# vpac_targetdb register map
Vendor: Texas Instruments
Registers are 32-bit, read-write, no defined reset value unless marked. A register's access mark holds for its fields unless they carry their own. Offsets are as the file gives them; [hi:lo] are bit positions; {n}, {i} and the like mark numbered series; 'fields as' and 'values as' point back to an identical list.

## VPAC (part 6 of 8) — Vision Pre-Processing Accelerator (VPAC)
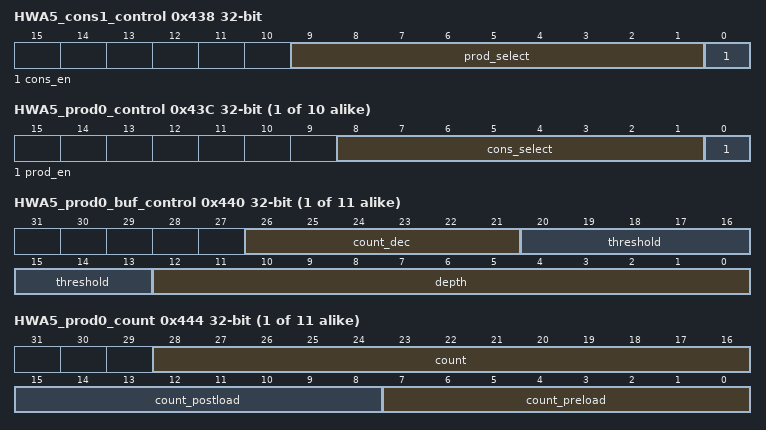
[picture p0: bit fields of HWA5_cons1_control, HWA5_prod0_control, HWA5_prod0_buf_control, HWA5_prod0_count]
0x438 HWA5_cons1_control — Controlling consumer socket 1 for HWA5
  [9:1] prod_select — producer select for HWA5 cons socket 1
  [0] cons_en — '1' -> Consumer socket 1 enable , '0' Disable
{0x43C+0x14*i} HWA5_prod{i}_control (i=0..9) — Controlling producer socket{i} for HWA5
  [8:1] cons_select — consumer select for HWA5 prod socket {i}. Used in decrementing count of producer buffer
  [0] prod_en — '1' -> Producer socket 0 enable , '0' Disable
{0x440+0x14*i} HWA5_prod{i}_buf_control (i=0..10) — Controlling producer socket{i} buffer for HWA5
  [26:21] count_dec — Count decrement value for prod count
  [20:13] threshold — Count threshold to generate pend for consumer
  [12:0] depth — Maximum number of producer buffer count
{0x444+0x14*i} HWA5_prod{i}_count access per field (i=0..10) — Defining count values for pre/post load for generating pend by HWA5 prod{i}
  [28:16] count ro — current count value
  [15:8] count_postload rw — count postload after producer max thread count reached
  [7:0] count_preload rw — count preload after scheduler start/init
{0x2D4+4i} GLBCE_WDR_GAMMA_LUT_{i} access per field (i=100..256) — Frontend WDR LUT
  [15:0] VAL rw — LUT Value
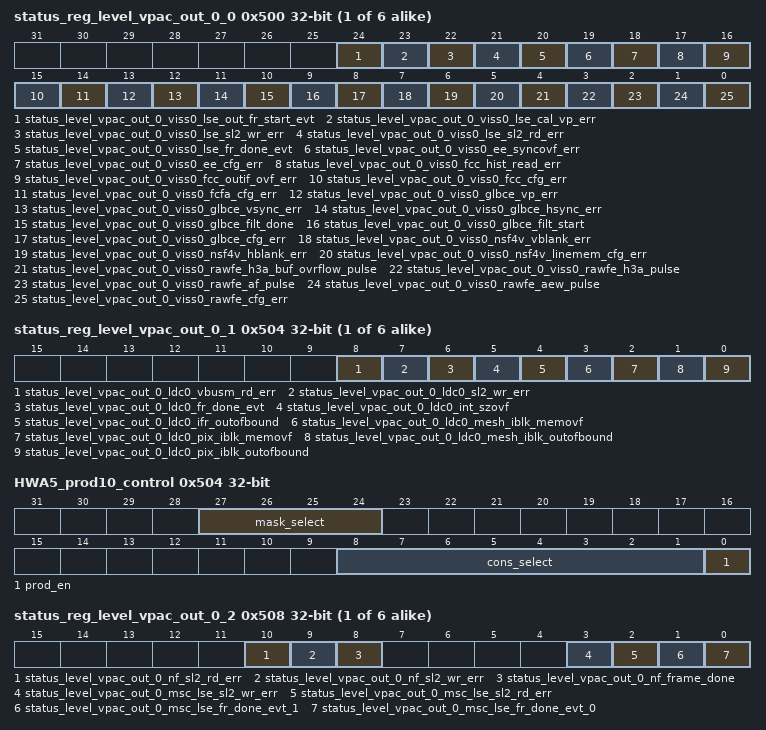
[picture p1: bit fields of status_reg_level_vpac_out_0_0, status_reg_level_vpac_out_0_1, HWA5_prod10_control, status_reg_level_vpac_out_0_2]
{0x500+0x20*i} status_reg_level_vpac_out_{i}_0 (i=0..5) — Status Register {8i}
  [24] status_level_vpac_out_{i}_viss0_lse_out_fr_start_evt — Status ,write 1 to set, for level_vpac_out_{i}_en_viss0_lse_out_fr_start_evt
  [23] status_level_vpac_out_{i}_viss0_lse_cal_vp_err — Status ,write 1 to set, for level_vpac_out_{i}_en_viss0_lse_cal_vp_err
  [22] status_level_vpac_out_{i}_viss0_lse_sl2_wr_err — Status ,write 1 to set, for level_vpac_out_{i}_en_viss0_lse_sl2_wr_err
  [21] status_level_vpac_out_{i}_viss0_lse_sl2_rd_err — Status ,write 1 to set, for level_vpac_out_{i}_en_viss0_lse_sl2_rd_err
  [20] status_level_vpac_out_{i}_viss0_lse_fr_done_evt — Status ,write 1 to set, for level_vpac_out_{i}_en_viss0_lse_fr_done_evt
  [19] status_level_vpac_out_{i}_viss0_ee_syncovf_err — Status ,write 1 to set, for level_vpac_out_{i}_en_viss0_ee_syncovf_err
  [18] status_level_vpac_out_{i}_viss0_ee_cfg_err — Status ,write 1 to set, for level_vpac_out_{i}_en_viss0_ee_cfg_err
  [17] status_level_vpac_out_{i}_viss0_fcc_hist_read_err — Status ,write 1 to set, for level_vpac_out_{i}_en_viss0_fcc_hist_read_err
  [16] status_level_vpac_out_{i}_viss0_fcc_outif_ovf_err — Status ,write 1 to set, for level_vpac_out_{i}_en_viss0_fcc_outif_ovf_err
  [15] status_level_vpac_out_{i}_viss0_fcc_cfg_err — Status ,write 1 to set, for level_vpac_out_{i}_en_viss0_fcc_cfg_err
  [14] status_level_vpac_out_{i}_viss0_fcfa_cfg_err — Status ,write 1 to set, for level_vpac_out_{i}_en_viss0_fcfa_cfg_err
  [13] status_level_vpac_out_{i}_viss0_glbce_vp_err — Status ,write 1 to set, for level_vpac_out_{i}_en_viss0_glbce_vp_err
  [12] status_level_vpac_out_{i}_viss0_glbce_vsync_err — Status ,write 1 to set, for level_vpac_out_{i}_en_viss0_glbce_vsync_err
  [11] status_level_vpac_out_{i}_viss0_glbce_hsync_err — Status ,write 1 to set, for level_vpac_out_{i}_en_viss0_glbce_hsync_err
  [10] status_level_vpac_out_{i}_viss0_glbce_filt_done — Status ,write 1 to set, for level_vpac_out_{i}_en_viss0_glbce_filt_done
  [9] status_level_vpac_out_{i}_viss0_glbce_filt_start — Status ,write 1 to set, for level_vpac_out_{i}_en_viss0_glbce_filt_start
  [8] status_level_vpac_out_{i}_viss0_glbce_cfg_err — Status ,write 1 to set, for level_vpac_out_{i}_en_viss0_glbce_cfg_err
  [7] status_level_vpac_out_{i}_viss0_nsf4v_vblank_err — Status ,write 1 to set, for level_vpac_out_{i}_en_viss0_nsf4v_vblank_err
  [6] status_level_vpac_out_{i}_viss0_nsf4v_hblank_err — Status ,write 1 to set, for level_vpac_out_{i}_en_viss0_nsf4v_hblank_err
  [5] status_level_vpac_out_{i}_viss0_nsf4v_linemem_cfg_err — Status ,write 1 to set, for level_vpac_out_{i}_en_viss0_nsf4v_linemem_cfg_err
  [4] status_level_vpac_out_{i}_viss0_rawfe_h3a_buf_ovrflow_pulse — Status ,write 1 to set, for level_vpac_out_{i}_en_viss0_rawfe_h3a_buf_ovrflow_pulse
  [3] status_level_vpac_out_{i}_viss0_rawfe_h3a_pulse — Status ,write 1 to set, for level_vpac_out_{i}_en_viss0_rawfe_h3a_pulse
  [2] status_level_vpac_out_{i}_viss0_rawfe_af_pulse — Status ,write 1 to set, for level_vpac_out_{i}_en_viss0_rawfe_af_pulse
  [1] status_level_vpac_out_{i}_viss0_rawfe_aew_pulse — Status ,write 1 to set, for level_vpac_out_{i}_en_viss0_rawfe_aew_pulse
  [0] status_level_vpac_out_{i}_viss0_rawfe_cfg_err — Status ,write 1 to set, for level_vpac_out_{i}_en_viss0_rawfe_cfg_err
{0x504+0x20*i} status_reg_level_vpac_out_{i}_1 (i=0..5) — Status Register {8i+1}
  [8] status_level_vpac_out_{i}_ldc0_vbusm_rd_err — Status ,write 1 to set, for level_vpac_out_{i}_en_ldc0_vbusm_rd_err
  [7] status_level_vpac_out_{i}_ldc0_sl2_wr_err — Status ,write 1 to set, for level_vpac_out_{i}_en_ldc0_sl2_wr_err
  [6] status_level_vpac_out_{i}_ldc0_fr_done_evt — Status ,write 1 to set, for level_vpac_out_{i}_en_ldc0_fr_done_evt
  [5] status_level_vpac_out_{i}_ldc0_int_szovf — Status ,write 1 to set, for level_vpac_out_{i}_en_ldc0_int_szovf
  [4] status_level_vpac_out_{i}_ldc0_ifr_outofbound — Status ,write 1 to set, for level_vpac_out_{i}_en_ldc0_ifr_outofbound
  [3] status_level_vpac_out_{i}_ldc0_mesh_iblk_memovf — Status ,write 1 to set, for level_vpac_out_{i}_en_ldc0_mesh_iblk_memovf
  [2] status_level_vpac_out_{i}_ldc0_pix_iblk_memovf — Status ,write 1 to set, for level_vpac_out_{i}_en_ldc0_pix_iblk_memovf
  [1] status_level_vpac_out_{i}_ldc0_mesh_iblk_outofbound — Status ,write 1 to set, for level_vpac_out_{i}_en_ldc0_mesh_iblk_outofbound
  [0] status_level_vpac_out_{i}_ldc0_pix_iblk_outofbound — Status ,write 1 to set, for level_vpac_out_{i}_en_ldc0_pix_iblk_outofbound
0x504 HWA5_prod10_control — Controlling producer socket10 for HWA5
  [27:24] mask_select — define which tdone_mask apply to prod socket 10. tdone_mask[mask_select] applies to prod_socket10
  [8:1] cons_select — consumer select for HWA5 prod socket 10. Used in decrementing count of producer buffer
  [0] prod_en — '1' -> Producer socket 0 enable , '0' Disable
{0x508+0x20*i} status_reg_level_vpac_out_{i}_2 (i=0..5) — Status Register {8i+2}
  [10] status_level_vpac_out_{i}_nf_sl2_rd_err — Status ,write 1 to set, for level_vpac_out_{i}_en_nf_sl2_rd_err
  [9] status_level_vpac_out_{i}_nf_sl2_wr_err — Status ,write 1 to set, for level_vpac_out_{i}_en_nf_sl2_wr_err
  [8] status_level_vpac_out_{i}_nf_frame_done — Status ,write 1 to set, for level_vpac_out_{i}_en_nf_frame_done
  [3] status_level_vpac_out_{i}_msc_lse_sl2_wr_err — Status ,write 1 to set, for level_vpac_out_{i}_en_msc_lse_sl2_wr_err
  [2] status_level_vpac_out_{i}_msc_lse_sl2_rd_err — Status ,write 1 to set, for level_vpac_out_{i}_en_msc_lse_sl2_rd_err
  [1] status_level_vpac_out_{i}_msc_lse_fr_done_evt_1 — Status ,write 1 to set, for level_vpac_out_{i}_en_msc_lse_fr_done_evt_1
  [0] status_level_vpac_out_{i}_msc_lse_fr_done_evt_0 — Status ,write 1 to set, for level_vpac_out_{i}_en_msc_lse_fr_done_evt_0
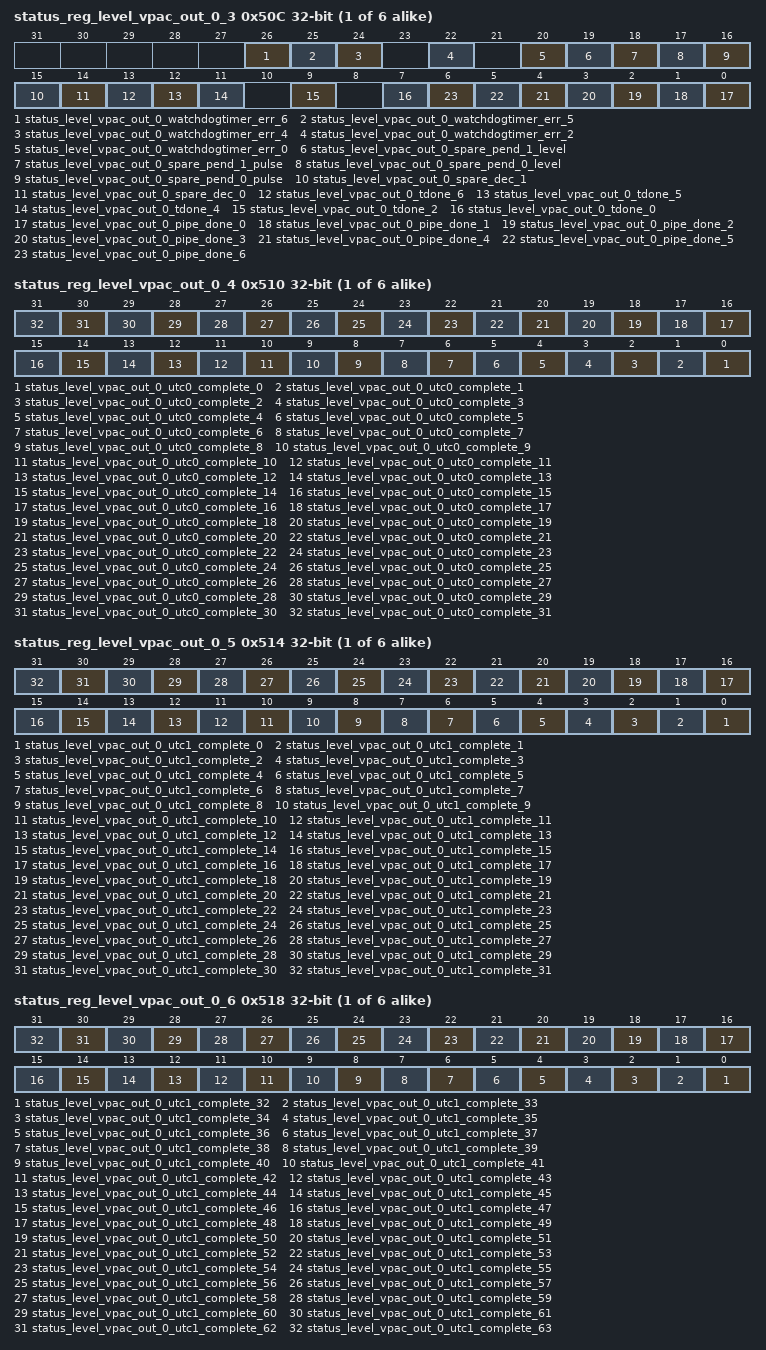
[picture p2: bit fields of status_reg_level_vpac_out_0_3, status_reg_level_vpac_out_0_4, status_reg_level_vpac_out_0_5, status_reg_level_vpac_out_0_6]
{0x50C+0x20*i} status_reg_level_vpac_out_{i}_3 access per field (i=0..5) — Status Register {8i+3}
  [26] status_level_vpac_out_{i}_watchdogtimer_err_6 rw — Status ,write 1 to set, for level_vpac_out_{i}_en_watchdogtimer_err_6
  [25] status_level_vpac_out_{i}_watchdogtimer_err_5 rw — Status ,write 1 to set, for level_vpac_out_{i}_en_watchdogtimer_err_5
  [24] status_level_vpac_out_{i}_watchdogtimer_err_4 rw — Status ,write 1 to set, for level_vpac_out_{i}_en_watchdogtimer_err_4
  [22] status_level_vpac_out_{i}_watchdogtimer_err_2 rw — Status ,write 1 to set, for level_vpac_out_{i}_en_watchdogtimer_err_2
  [20] status_level_vpac_out_{i}_watchdogtimer_err_0 rw — Status ,write 1 to set, for level_vpac_out_{i}_en_watchdogtimer_err_0
  [19] status_level_vpac_out_{i}_spare_pend_1_level ro — Status for level_vpac_out_{i}_en_spare_pend_1_level
  [18] status_level_vpac_out_{i}_spare_pend_1_pulse ro — Status for level_vpac_out_{i}_en_spare_pend_1_pulse
  [17] status_level_vpac_out_{i}_spare_pend_0_level ro — Status for level_vpac_out_{i}_en_spare_pend_0_level
  [16] status_level_vpac_out_{i}_spare_pend_0_pulse ro — Status for level_vpac_out_{i}_en_spare_pend_0_pulse
  [15] status_level_vpac_out_{i}_spare_dec_1 rw — Status ,write 1 to set, for level_vpac_out_{i}_en_spare_dec_1
  [14] status_level_vpac_out_{i}_spare_dec_0 rw — Status ,write 1 to set, for level_vpac_out_{i}_en_spare_dec_0
  [13] status_level_vpac_out_{i}_tdone_6 rw — Status ,write 1 to set, for level_vpac_out_{i}_en_tdone_6
  [12] status_level_vpac_out_{i}_tdone_5 rw — Status ,write 1 to set, for level_vpac_out_{i}_en_tdone_5
  [11] status_level_vpac_out_{i}_tdone_4 rw — Status ,write 1 to set, for level_vpac_out_{i}_en_tdone_4
  [9] status_level_vpac_out_{i}_tdone_2 rw — Status ,write 1 to set, for level_vpac_out_{i}_en_tdone_2
  [7] status_level_vpac_out_{i}_tdone_0 rw — Status ,write 1 to set, for level_vpac_out_{i}_en_tdone_0
  [n] status_level_vpac_out_{i}_pipe_done_{n} rw (n=0..6) — Status ,write 1 to set, for level_vpac_out_{i}_en_pipe_done_{n}
{0x510+0x20*i} status_reg_level_vpac_out_{i}_4 (i=0..5) — Status Register {8i+4}
  [n] status_level_vpac_out_{i}_utc0_complete_{n} (n=0..31) — Status ,write 1 to set, for level_vpac_out_{i}_en_utc0_complete_{n}
{0x514+0x20*i} status_reg_level_vpac_out_{i}_5 (i=0..5) — Status Register {8i+5}
  [n] status_level_vpac_out_{i}_utc1_complete_{n} (n=0..31) — Status ,write 1 to set, for level_vpac_out_{i}_en_utc1_complete_{n}
{0x518+0x20*i} status_reg_level_vpac_out_{i}_6 (i=0..5) — Status Register {8i+6}
  [n-32] status_level_vpac_out_{i}_utc1_complete_{n} (n=32..63) — Status ,write 1 to set, for level_vpac_out_{i}_en_utc1_complete_{n}
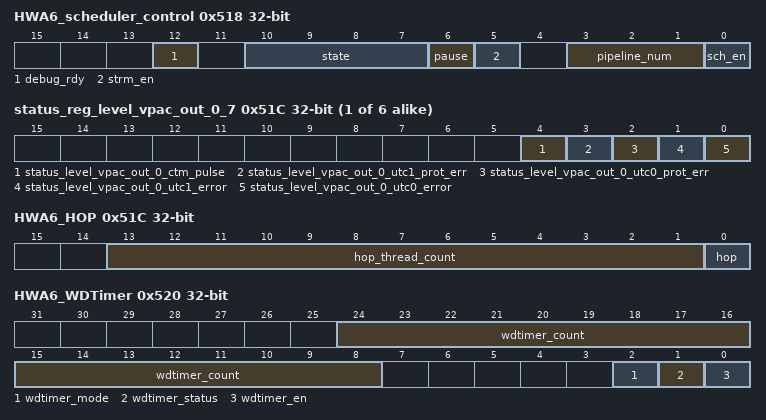
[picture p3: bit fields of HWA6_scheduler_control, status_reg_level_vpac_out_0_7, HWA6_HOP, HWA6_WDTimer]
0x518 HWA6_scheduler_control access per field — Scheduler Control Register
  [12] debug_rdy rw — '0' -> HWA6 Scheduler resources must not be read during halted state. '1'-> HWA6 Scheduler resources are readable during halted state
  [10:7] state ro — Current state of HWA6 Scheduler
  [6] pause rw — '1' -> pause/suspend scheduler , '0' -> resume scheduler
  [5] strm_en rw — '1' -> Streaming input enable, '0' No streaming input
  [3:1] pipeline_num rw — Pipeline Number of HWA6 Scheduler
  [0] sch_en rw — scheduler enable; write '1' to enable scheduler
{0x51C+0x20*i} status_reg_level_vpac_out_{i}_7 (i=0..5) — Status Register {8i+7}
  [4] status_level_vpac_out_{i}_ctm_pulse — Status ,write 1 to set, for level_vpac_out_{i}_en_ctm_pulse
  [3] status_level_vpac_out_{i}_utc1_prot_err — Status ,write 1 to set, for level_vpac_out_{i}_en_utc1_prot_err
  [2] status_level_vpac_out_{i}_utc0_prot_err — Status ,write 1 to set, for level_vpac_out_{i}_en_utc0_prot_err
  [1] status_level_vpac_out_{i}_utc1_error — Status ,write 1 to set, for level_vpac_out_{i}_en_utc1_error
  [0] status_level_vpac_out_{i}_utc0_error — Status ,write 1 to set, for level_vpac_out_{i}_en_utc0_error
0x51C HWA6_HOP — Scheduler HOP Control Register. Help in detecting eop within scheduler. Once configured, it counts task/channel starts and stops issuing further starts. Specifically useful for Head of pipe dma scheduler .
  [13:1] hop_thread_count — Number of Task count for Head of pipe
  [0] hop — '1' -> Head of Pipe producer Sch , '0' -> No hop
0x520 HWA6_WDTimer access per field — Watchdog timer control register
  [24:8] wdtimer_count ro — Current value of HWA6 Scheduler watchdog timer count
  [2] wdtimer_mode rw — Watchdog timeout count '1' -> 128K , '0' -> 64K
  [1] wdtimer_status ro — HWA6 Scheduler watchdog timer status '1' -> Timer Active '0' -> Timer Inactive (count is stable)
  [0] wdtimer_en rw — '1' -> activate watchdog timer for 64K VPAC/DMPAC cycles between task start and task done '0' -> Disable watchdog timer
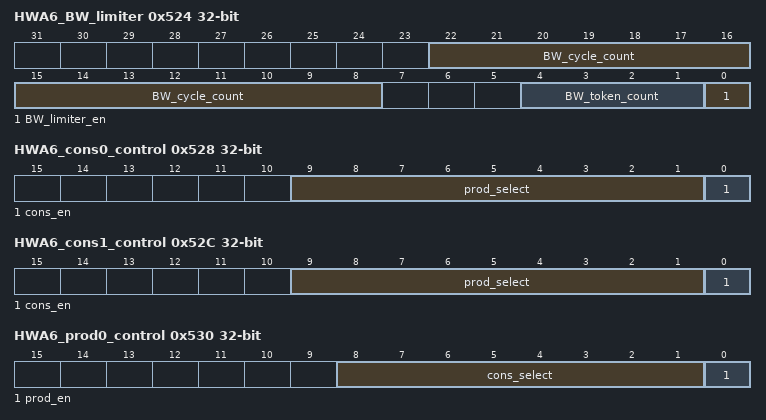
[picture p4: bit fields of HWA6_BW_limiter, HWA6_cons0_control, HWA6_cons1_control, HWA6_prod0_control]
0x524 HWA6_BW_limiter — Scheduler BW Control Register. Processing unit level BW control. Use DMA to eliminate peak system BW within processing units line/Block
  [22:8] BW_cycle_count — Average Cycle count between successive Task Start
  [4:1] BW_token_count — Max Token count to create average BW
  [0] BW_limiter_en — '1' -> Enable BW limiter function for HWA6 sch, '0' --> Disable
0x528 HWA6_cons0_control — Controlling consumer socket 0 for HWA6
  [9:1] prod_select — producer select for HWA6 cons socket 0
  [0] cons_en — '1' -> Consumer socket 0 enable , '0' Disable
0x52C HWA6_cons1_control — Controlling consumer socket 1 for HWA6
  [9:1] prod_select — producer select for HWA6 cons socket 1
  [0] cons_en — '1' -> Consumer socket 1 enable , '0' Disable
0x530 HWA6_prod0_control — Controlling producer socket0 for HWA6
  [8:1] cons_select — consumer select for HWA6 prod socket 0. Used in decrementing count of producer buffer
  [0] prod_en — '1' -> Producer socket 0 enable , '0' Disable
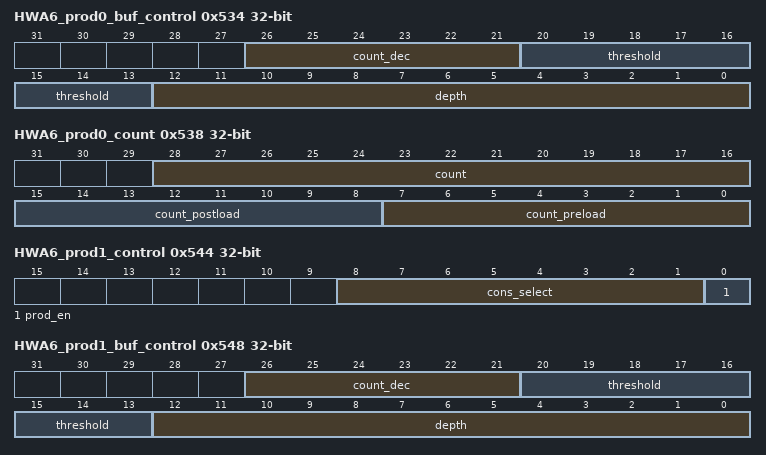
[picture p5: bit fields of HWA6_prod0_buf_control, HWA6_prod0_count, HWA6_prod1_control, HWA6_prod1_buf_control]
0x534 HWA6_prod0_buf_control — Controlling producer socket0 buffer for HWA6
  fields as HWA5_prod0_buf_control
0x538 HWA6_prod0_count access per field — Defining count values for pre/post load for generating pend by HWA6 prod0
  fields as HWA5_prod0_count
0x544 HWA6_prod1_control — Controlling producer socket1 for HWA6
  [8:1] cons_select — consumer select for HWA6 prod socket 1. Used in decrementing count of producer buffer
  [0] prod_en — '1' -> Producer socket 0 enable , '0' Disable
0x548 HWA6_prod1_buf_control — Controlling producer socket1 buffer for HWA6
  fields as HWA5_prod0_buf_control
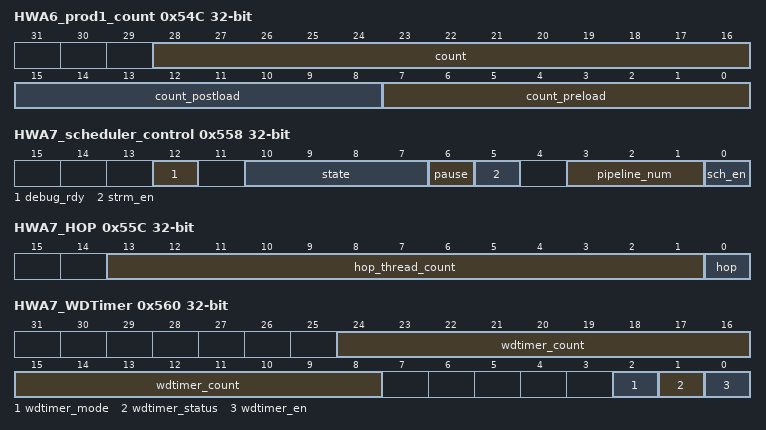
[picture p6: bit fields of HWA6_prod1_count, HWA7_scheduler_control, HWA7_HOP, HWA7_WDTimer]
0x54C HWA6_prod1_count access per field — Defining count values for pre/post load for generating pend by HWA6 prod1
  fields as HWA5_prod0_count
0x558 HWA7_scheduler_control access per field — Scheduler Control Register
  [12] debug_rdy rw — '0' -> HWA7 Scheduler resources must not be read during halted state. '1'-> HWA7 Scheduler resources are readable during halted state
  [10:7] state ro — Current state of HWA7 Scheduler
  [6] pause rw — '1' -> pause/suspend scheduler , '0' -> resume scheduler
  [5] strm_en rw — '1' -> Streaming input enable, '0' No streaming input
  [3:1] pipeline_num rw — Pipeline Number of HWA7 Scheduler
  [0] sch_en rw — scheduler enable; write '1' to enable scheduler
0x55C HWA7_HOP — Scheduler HOP Control Register. Help in detecting eop within scheduler. Once configured, it counts task/channel starts and stops issuing further start. Specifically useful for Head of pipe dma scheduler .
  fields as HWA6_HOP
0x560 HWA7_WDTimer access per field — Watchdog timer control register
  [24:8] wdtimer_count ro — Current value of HWA7 Scheduler watchdog timer count
  [2] wdtimer_mode rw — Watchdog timeout count '1' -> 128K , '0' -> 64K
  [1] wdtimer_status ro — HWA7 Scheduler watchdog timer status '1' -> Timer Active '0' -> Timer Inactive (count is stable)
  [0] wdtimer_en rw — '1' -> activate watchdog timer for 64K VPAC/DMPAC cycles between task start and task done '0' -> Disable watchdog timer
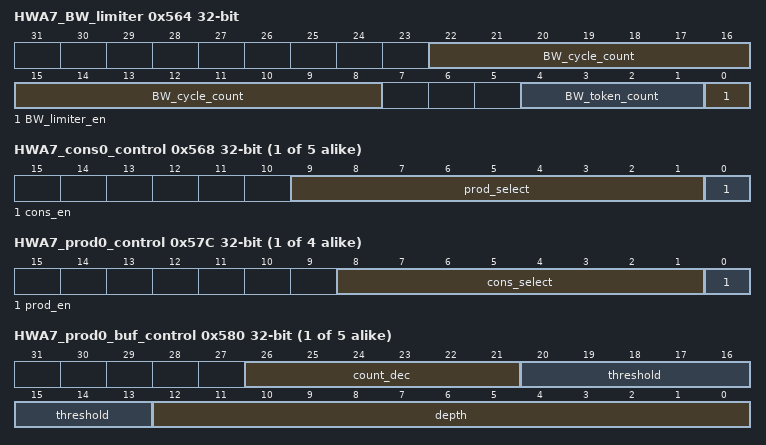
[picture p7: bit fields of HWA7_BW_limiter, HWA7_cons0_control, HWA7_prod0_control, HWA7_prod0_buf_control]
0x564 HWA7_BW_limiter — Scheduler BW Control Register. Processing unit level BW control. Use DMA to eliminate peak system BW within processing units line/Block
  [22:8] BW_cycle_count — Average Cycle count between successive Task Start
  [4:1] BW_token_count — Max Token count to create average BW
  [0] BW_limiter_en — '1' -> Enable BW limiter function for HWA7 sch, '0' --> Disable
{0x568+4i} HWA7_cons{i}_control (i=0..4) — Controlling consumer socket {i} for HWA7
  [9:1] prod_select — producer select for HWA7 cons socket {i}
  [0] cons_en — '1' -> Consumer socket {i} enable , '0' Disable
{0x57C+0x14*i} HWA7_prod{i}_control (i=0..3) — Controlling producer socket{i} for HWA7
  [8:1] cons_select — consumer select for HWA7 prod socket {i}. Used in decrementing count of producer buffer
  [0] prod_en — '1' -> Producer socket 0 enable , '0' Disable
{0x580+0x14*i} HWA7_prod{i}_buf_control (i=0..4) — Controlling producer socket{i} buffer for HWA7
  fields as HWA5_prod0_buf_control
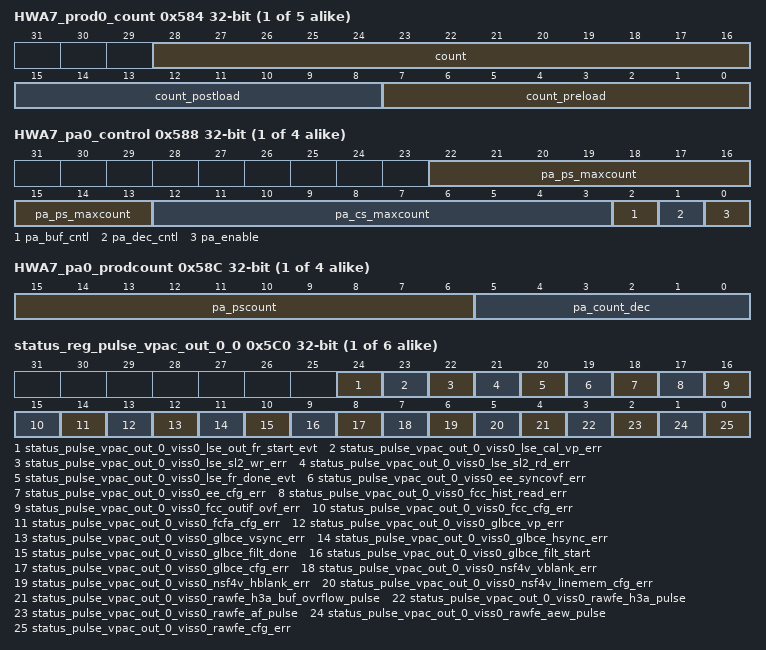
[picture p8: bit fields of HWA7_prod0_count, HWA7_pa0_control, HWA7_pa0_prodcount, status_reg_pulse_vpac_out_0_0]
{0x584+0x14*i} HWA7_prod{i}_count access per field (i=0..4) — Defining count values for pre/post load for generating pend by HWA7 prod{i}
  fields as HWA5_prod0_count
{0x588+0x14*i} HWA7_pa{i}_control (i=0..3) — control register to manage pattern adapter on HWA7 prod socket{i}
  [22:13] pa_ps_maxcount — destination count for pattern adaptation (N), M --> N
  [12:3] pa_cs_maxcount — source count for pattern adaptation (M), M --> N
  [2] pa_buf_cntl — '1' -> Apply threshold, count_preload and count_postload on pattern adapter count (use this only when pa_enable='1') '0' -> Apply threshold, count_preload and count_postload on prod count (same behavior as if no pattern adapter. Note when pa_enable='1' and pa_buf_cntl='0' threshold is not used and ignored)
  [1] pa_dec_cntl — '1' -> post pattern adaptation, decrement ps count by count_dec , '0' -> post pattern adaptation, decrement ps count by pa_cs_maxcount
  [0] pa_enable — '1' -> pa enable, '0' -> disable
{0x58C+0x14*i} HWA7_pa{i}_prodcount access per field (i=0..3) — count values for HWA7 prod socket{i}
  [15:6] pa_pscount ro — current count value of pa prod count
  [5:0] pa_count_dec rw — Decrement count value of pa_prod_count after pattern adapter prod count reaches threshold
{0x5C0+0x20*i} status_reg_pulse_vpac_out_{i}_0 (i=0..5) — Status Register {8i+48}
  [24] status_pulse_vpac_out_{i}_viss0_lse_out_fr_start_evt — Status ,write 1 to set, for pulse_vpac_out_{i}_en_viss0_lse_out_fr_start_evt
  [23] status_pulse_vpac_out_{i}_viss0_lse_cal_vp_err — Status ,write 1 to set, for pulse_vpac_out_{i}_en_viss0_lse_cal_vp_err
  [22] status_pulse_vpac_out_{i}_viss0_lse_sl2_wr_err — Status ,write 1 to set, for pulse_vpac_out_{i}_en_viss0_lse_sl2_wr_err
  [21] status_pulse_vpac_out_{i}_viss0_lse_sl2_rd_err — Status ,write 1 to set, for pulse_vpac_out_{i}_en_viss0_lse_sl2_rd_err
  [20] status_pulse_vpac_out_{i}_viss0_lse_fr_done_evt — Status ,write 1 to set, for pulse_vpac_out_{i}_en_viss0_lse_fr_done_evt
  [19] status_pulse_vpac_out_{i}_viss0_ee_syncovf_err — Status ,write 1 to set, for pulse_vpac_out_{i}_en_viss0_ee_syncovf_err
  [18] status_pulse_vpac_out_{i}_viss0_ee_cfg_err — Status ,write 1 to set, for pulse_vpac_out_{i}_en_viss0_ee_cfg_err
  [17] status_pulse_vpac_out_{i}_viss0_fcc_hist_read_err — Status ,write 1 to set, for pulse_vpac_out_{i}_en_viss0_fcc_hist_read_err
  [16] status_pulse_vpac_out_{i}_viss0_fcc_outif_ovf_err — Status ,write 1 to set, for pulse_vpac_out_{i}_en_viss0_fcc_outif_ovf_err
  [15] status_pulse_vpac_out_{i}_viss0_fcc_cfg_err — Status ,write 1 to set, for pulse_vpac_out_{i}_en_viss0_fcc_cfg_err
  [14] status_pulse_vpac_out_{i}_viss0_fcfa_cfg_err — Status ,write 1 to set, for pulse_vpac_out_{i}_en_viss0_fcfa_cfg_err
  [13] status_pulse_vpac_out_{i}_viss0_glbce_vp_err — Status ,write 1 to set, for pulse_vpac_out_{i}_en_viss0_glbce_vp_err
  [12] status_pulse_vpac_out_{i}_viss0_glbce_vsync_err — Status ,write 1 to set, for pulse_vpac_out_{i}_en_viss0_glbce_vsync_err
  [11] status_pulse_vpac_out_{i}_viss0_glbce_hsync_err — Status ,write 1 to set, for pulse_vpac_out_{i}_en_viss0_glbce_hsync_err
  [10] status_pulse_vpac_out_{i}_viss0_glbce_filt_done — Status ,write 1 to set, for pulse_vpac_out_{i}_en_viss0_glbce_filt_done
  [9] status_pulse_vpac_out_{i}_viss0_glbce_filt_start — Status ,write 1 to set, for pulse_vpac_out_{i}_en_viss0_glbce_filt_start
  [8] status_pulse_vpac_out_{i}_viss0_glbce_cfg_err — Status ,write 1 to set, for pulse_vpac_out_{i}_en_viss0_glbce_cfg_err
  [7] status_pulse_vpac_out_{i}_viss0_nsf4v_vblank_err — Status ,write 1 to set, for pulse_vpac_out_{i}_en_viss0_nsf4v_vblank_err
  [6] status_pulse_vpac_out_{i}_viss0_nsf4v_hblank_err — Status ,write 1 to set, for pulse_vpac_out_{i}_en_viss0_nsf4v_hblank_err
  [5] status_pulse_vpac_out_{i}_viss0_nsf4v_linemem_cfg_err — Status ,write 1 to set, for pulse_vpac_out_{i}_en_viss0_nsf4v_linemem_cfg_err
  [4] status_pulse_vpac_out_{i}_viss0_rawfe_h3a_buf_ovrflow_pulse — Status ,write 1 to set, for pulse_vpac_out_{i}_en_viss0_rawfe_h3a_buf_ovrflow_pulse
  [3] status_pulse_vpac_out_{i}_viss0_rawfe_h3a_pulse — Status ,write 1 to set, for pulse_vpac_out_{i}_en_viss0_rawfe_h3a_pulse
  [2] status_pulse_vpac_out_{i}_viss0_rawfe_af_pulse — Status ,write 1 to set, for pulse_vpac_out_{i}_en_viss0_rawfe_af_pulse
  [1] status_pulse_vpac_out_{i}_viss0_rawfe_aew_pulse — Status ,write 1 to set, for pulse_vpac_out_{i}_en_viss0_rawfe_aew_pulse
  [0] status_pulse_vpac_out_{i}_viss0_rawfe_cfg_err — Status ,write 1 to set, for pulse_vpac_out_{i}_en_viss0_rawfe_cfg_err
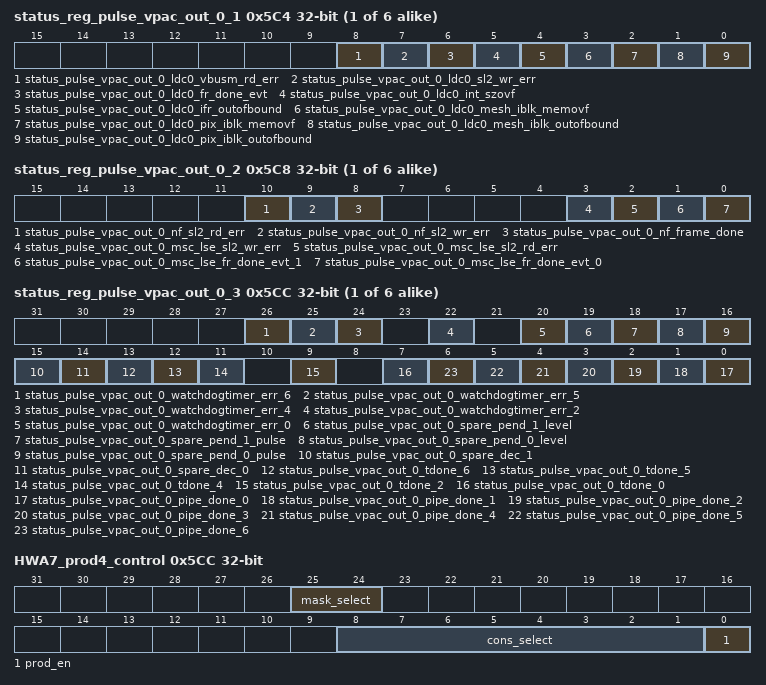
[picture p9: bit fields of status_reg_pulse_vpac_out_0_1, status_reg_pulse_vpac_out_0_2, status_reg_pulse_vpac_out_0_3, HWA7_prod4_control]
{0x5C4+0x20*i} status_reg_pulse_vpac_out_{i}_1 (i=0..5) — Status Register {8i+49}
  [8] status_pulse_vpac_out_{i}_ldc0_vbusm_rd_err — Status ,write 1 to set, for pulse_vpac_out_{i}_en_ldc0_vbusm_rd_err
  [7] status_pulse_vpac_out_{i}_ldc0_sl2_wr_err — Status ,write 1 to set, for pulse_vpac_out_{i}_en_ldc0_sl2_wr_err
  [6] status_pulse_vpac_out_{i}_ldc0_fr_done_evt — Status ,write 1 to set, for pulse_vpac_out_{i}_en_ldc0_fr_done_evt
  [5] status_pulse_vpac_out_{i}_ldc0_int_szovf — Status ,write 1 to set, for pulse_vpac_out_{i}_en_ldc0_int_szovf
  [4] status_pulse_vpac_out_{i}_ldc0_ifr_outofbound — Status ,write 1 to set, for pulse_vpac_out_{i}_en_ldc0_ifr_outofbound
  [3] status_pulse_vpac_out_{i}_ldc0_mesh_iblk_memovf — Status ,write 1 to set, for pulse_vpac_out_{i}_en_ldc0_mesh_iblk_memovf
  [2] status_pulse_vpac_out_{i}_ldc0_pix_iblk_memovf — Status ,write 1 to set, for pulse_vpac_out_{i}_en_ldc0_pix_iblk_memovf
  [1] status_pulse_vpac_out_{i}_ldc0_mesh_iblk_outofbound — Status ,write 1 to set, for pulse_vpac_out_{i}_en_ldc0_mesh_iblk_outofbound
  [0] status_pulse_vpac_out_{i}_ldc0_pix_iblk_outofbound — Status ,write 1 to set, for pulse_vpac_out_{i}_en_ldc0_pix_iblk_outofbound
{0x5C8+0x20*i} status_reg_pulse_vpac_out_{i}_2 (i=0..5) — Status Register {8i+50}
  [10] status_pulse_vpac_out_{i}_nf_sl2_rd_err — Status ,write 1 to set, for pulse_vpac_out_{i}_en_nf_sl2_rd_err
  [9] status_pulse_vpac_out_{i}_nf_sl2_wr_err — Status ,write 1 to set, for pulse_vpac_out_{i}_en_nf_sl2_wr_err
  [8] status_pulse_vpac_out_{i}_nf_frame_done — Status ,write 1 to set, for pulse_vpac_out_{i}_en_nf_frame_done
  [3] status_pulse_vpac_out_{i}_msc_lse_sl2_wr_err — Status ,write 1 to set, for pulse_vpac_out_{i}_en_msc_lse_sl2_wr_err
  [2] status_pulse_vpac_out_{i}_msc_lse_sl2_rd_err — Status ,write 1 to set, for pulse_vpac_out_{i}_en_msc_lse_sl2_rd_err
  [1] status_pulse_vpac_out_{i}_msc_lse_fr_done_evt_1 — Status ,write 1 to set, for pulse_vpac_out_{i}_en_msc_lse_fr_done_evt_1
  [0] status_pulse_vpac_out_{i}_msc_lse_fr_done_evt_0 — Status ,write 1 to set, for pulse_vpac_out_{i}_en_msc_lse_fr_done_evt_0
{0x5CC+0x20*i} status_reg_pulse_vpac_out_{i}_3 access per field (i=0..5) — Status Register {8i+51}
  [26] status_pulse_vpac_out_{i}_watchdogtimer_err_6 rw — Status ,write 1 to set, for pulse_vpac_out_{i}_en_watchdogtimer_err_6
  [25] status_pulse_vpac_out_{i}_watchdogtimer_err_5 rw — Status ,write 1 to set, for pulse_vpac_out_{i}_en_watchdogtimer_err_5
  [24] status_pulse_vpac_out_{i}_watchdogtimer_err_4 rw — Status ,write 1 to set, for pulse_vpac_out_{i}_en_watchdogtimer_err_4
  [22] status_pulse_vpac_out_{i}_watchdogtimer_err_2 rw — Status ,write 1 to set, for pulse_vpac_out_{i}_en_watchdogtimer_err_2
  [20] status_pulse_vpac_out_{i}_watchdogtimer_err_0 rw — Status ,write 1 to set, for pulse_vpac_out_{i}_en_watchdogtimer_err_0
  [19] status_pulse_vpac_out_{i}_spare_pend_1_level ro — Status for pulse_vpac_out_{i}_en_spare_pend_1_level
  [18] status_pulse_vpac_out_{i}_spare_pend_1_pulse ro — Status for pulse_vpac_out_{i}_en_spare_pend_1_pulse
  [17] status_pulse_vpac_out_{i}_spare_pend_0_level ro — Status for pulse_vpac_out_{i}_en_spare_pend_0_level
  [16] status_pulse_vpac_out_{i}_spare_pend_0_pulse ro — Status for pulse_vpac_out_{i}_en_spare_pend_0_pulse
  [15] status_pulse_vpac_out_{i}_spare_dec_1 rw — Status ,write 1 to set, for pulse_vpac_out_{i}_en_spare_dec_1
  [14] status_pulse_vpac_out_{i}_spare_dec_0 rw — Status ,write 1 to set, for pulse_vpac_out_{i}_en_spare_dec_0
  [13] status_pulse_vpac_out_{i}_tdone_6 rw — Status ,write 1 to set, for pulse_vpac_out_{i}_en_tdone_6
  [12] status_pulse_vpac_out_{i}_tdone_5 rw — Status ,write 1 to set, for pulse_vpac_out_{i}_en_tdone_5
  [11] status_pulse_vpac_out_{i}_tdone_4 rw — Status ,write 1 to set, for pulse_vpac_out_{i}_en_tdone_4
  [9] status_pulse_vpac_out_{i}_tdone_2 rw — Status ,write 1 to set, for pulse_vpac_out_{i}_en_tdone_2
  [7] status_pulse_vpac_out_{i}_tdone_0 rw — Status ,write 1 to set, for pulse_vpac_out_{i}_en_tdone_0
  [n] status_pulse_vpac_out_{i}_pipe_done_{n} rw (n=0..6) — Status ,write 1 to set, for pulse_vpac_out_{i}_en_pipe_done_{n}
0x5CC HWA7_prod4_control — Controlling producer socket4 for HWA7
  [25:24] mask_select — define which tdone_mask apply to prod socket 4. tdone_mask[mask_select] applies to prod_socket4
  [8:1] cons_select — consumer select for HWA7 prod socket 4. Used in decrementing count of producer buffer
  [0] prod_en — '1' -> Producer socket 0 enable , '0' Disable
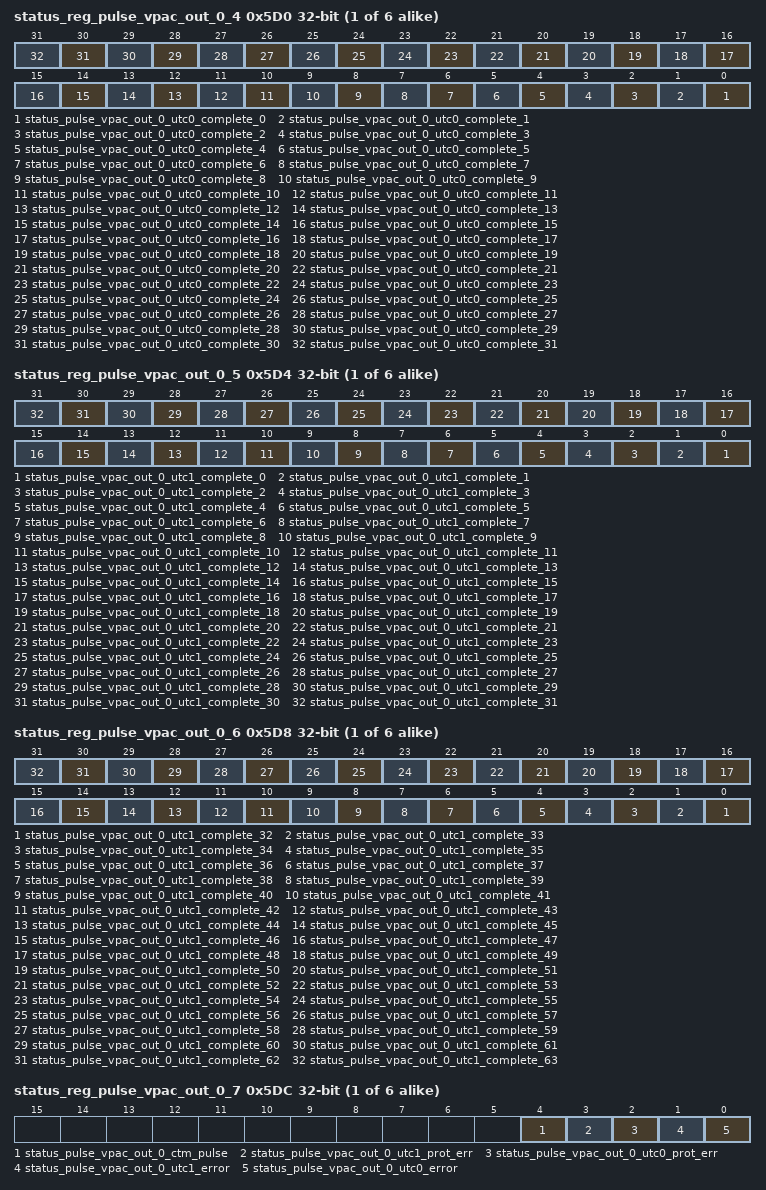
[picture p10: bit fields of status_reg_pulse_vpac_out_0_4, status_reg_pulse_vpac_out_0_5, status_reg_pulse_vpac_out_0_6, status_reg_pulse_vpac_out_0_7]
{0x5D0+0x20*i} status_reg_pulse_vpac_out_{i}_4 (i=0..5) — Status Register {8i+52}
  [n] status_pulse_vpac_out_{i}_utc0_complete_{n} (n=0..31) — Status ,write 1 to set, for pulse_vpac_out_{i}_en_utc0_complete_{n}
{0x5D4+0x20*i} status_reg_pulse_vpac_out_{i}_5 (i=0..5) — Status Register {8i+53}
  [n] status_pulse_vpac_out_{i}_utc1_complete_{n} (n=0..31) — Status ,write 1 to set, for pulse_vpac_out_{i}_en_utc1_complete_{n}
{0x5D8+0x20*i} status_reg_pulse_vpac_out_{i}_6 (i=0..5) — Status Register {8i+54}
  [n-32] status_pulse_vpac_out_{i}_utc1_complete_{n} (n=32..63) — Status ,write 1 to set, for pulse_vpac_out_{i}_en_utc1_complete_{n}
{0x5DC+0x20*i} status_reg_pulse_vpac_out_{i}_7 (i=0..5) — Status Register {8i+55}
  [4] status_pulse_vpac_out_{i}_ctm_pulse — Status ,write 1 to set, for pulse_vpac_out_{i}_en_ctm_pulse
  [3] status_pulse_vpac_out_{i}_utc1_prot_err — Status ,write 1 to set, for pulse_vpac_out_{i}_en_utc1_prot_err
  [2] status_pulse_vpac_out_{i}_utc0_prot_err — Status ,write 1 to set, for pulse_vpac_out_{i}_en_utc0_prot_err
  [1] status_pulse_vpac_out_{i}_utc1_error — Status ,write 1 to set, for pulse_vpac_out_{i}_en_utc1_error
  [0] status_pulse_vpac_out_{i}_utc0_error — Status ,write 1 to set, for pulse_vpac_out_{i}_en_utc0_error
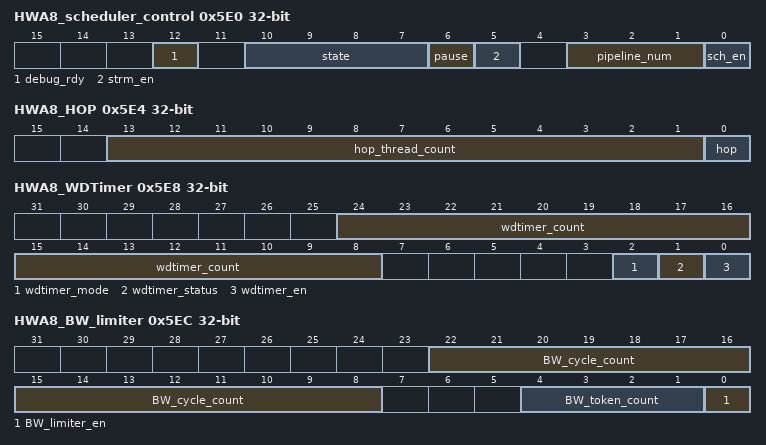
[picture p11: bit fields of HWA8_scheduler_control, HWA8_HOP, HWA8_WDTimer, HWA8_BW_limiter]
0x5E0 HWA8_scheduler_control access per field — Scheduler Control Register
  [12] debug_rdy rw — '0' -> HWA8 Scheduler resources must not be read during halted state. '1'-> HWA8 Scheduler resources are readable during halted state
  [10:7] state ro — Current state of HWA8 Scheduler
  [6] pause rw — '1' -> pause/suspend scheduler , '0' -> resume scheduler
  [5] strm_en rw — '1' -> Streaming input enable, '0' No streaming input
  [3:1] pipeline_num rw — Pipeline Number of HWA8 Scheduler
  [0] sch_en rw — scheduler enable; write '1' to enable scheduler
0x5E4 HWA8_HOP — Scheduler HOP Control Register. Help in detecting eop within scheduler. Once configured, it counts task/channel starts and stops issuing further start. Specifically useful for Head of pipe dma scheduler .
  fields as HWA6_HOP
0x5E8 HWA8_WDTimer access per field — Watchdog timer control register
  [24:8] wdtimer_count ro — Current value of HWA8 Scheduler watchdog timer count
  [2] wdtimer_mode rw — Watchdog timeout count '1' -> 128K , '0' -> 64K
  [1] wdtimer_status ro — HWA8 Scheduler watchdog timer status '1' -> Timer Active '0' -> Timer Inactive (count is stable)
  [0] wdtimer_en rw — '1' -> activate watchdog timer for 64K VPAC/DMPAC cycles between task start and task done '0' -> Disable watchdog timer
0x5EC HWA8_BW_limiter — Scheduler BW Control Register. Processing unit level BW control. Use DMA to eliminate peak system BW within processing units line/Block
  [22:8] BW_cycle_count — Average Cycle count between successive Task Start
  [4:1] BW_token_count — Max Token count to create average BW
  [0] BW_limiter_en — '1' -> Enable BW limiter function for HWA8 sch, '0' --> Disable
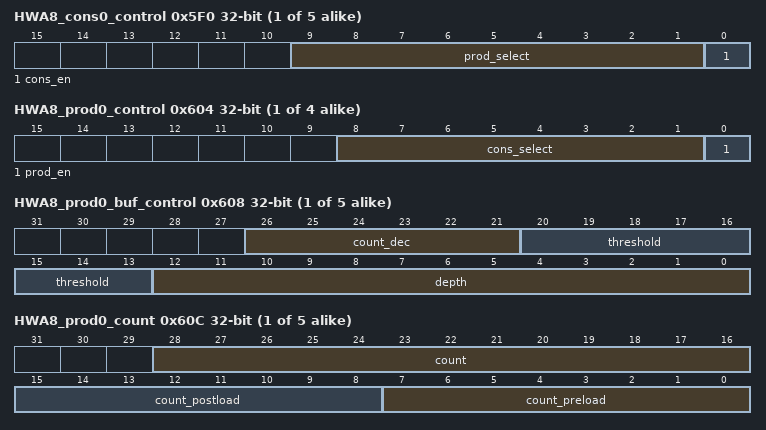
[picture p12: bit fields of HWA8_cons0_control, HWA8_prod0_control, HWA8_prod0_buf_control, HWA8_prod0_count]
{0x5F0+4i} HWA8_cons{i}_control (i=0..4) — Controlling consumer socket {i} for HWA8
  [9:1] prod_select — producer select for HWA8 cons socket {i}
  [0] cons_en — '1' -> Consumer socket {i} enable , '0' Disable
{0x604+0x14*i} HWA8_prod{i}_control (i=0..3) — Controlling producer socket{i} for HWA8
  [8:1] cons_select — consumer select for HWA8 prod socket {i}. Used in decrementing count of producer buffer
  [0] prod_en — '1' -> Producer socket 0 enable , '0' Disable
{0x608+0x14*i} HWA8_prod{i}_buf_control (i=0..4) — Controlling producer socket{i} buffer for HWA8
  fields as HWA5_prod0_buf_control
{0x60C+0x14*i} HWA8_prod{i}_count access per field (i=0..4) — Defining count values for pre/post load for generating pend by HWA8 prod{i}
  fields as HWA5_prod0_count
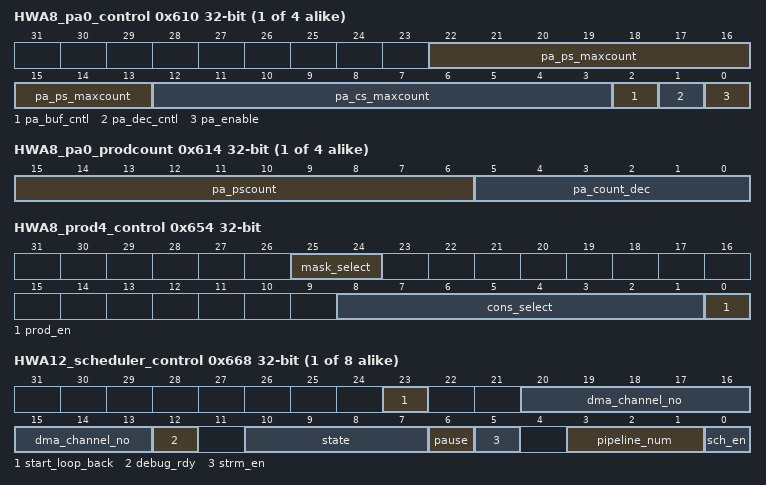
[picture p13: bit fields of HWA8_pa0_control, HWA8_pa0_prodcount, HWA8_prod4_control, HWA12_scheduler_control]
{0x610+0x14*i} HWA8_pa{i}_control (i=0..3) — control register to manage pattern adapter on HWA8 prod socket{i}
  fields as HWA7_pa0_control
{0x614+0x14*i} HWA8_pa{i}_prodcount access per field (i=0..3) — count values for HWA8 prod socket{i}
  fields as HWA7_pa0_prodcount
0x654 HWA8_prod4_control — Controlling producer socket4 for HWA8
  [25:24] mask_select — define which tdone_mask apply to prod socket 4. tdone_mask[mask_select] applies to prod_socket4
  [8:1] cons_select — consumer select for HWA8 prod socket 4. Used in decrementing count of producer buffer
  [0] prod_en — '1' -> Producer socket 0 enable , '0' Disable
{0x188+0x68*i} HWA{i}_scheduler_control access per field (i=12..19) — Scheduler Control Register
  [23] start_loop_back rw — '1' -> loop back start onto done in same cycle w/o asserting external channel start, '0' No loop back
  [20:13] dma_channel_no rw — DMA channel number for thread scheduler for HWA{i}
  [12] debug_rdy rw — '0' -> HWA{i} Scheduler resources must not be read during halted state. '1'-> HWA{i} Scheduler resources are readable during halted state
  [10:7] state ro — Current state of HWA{i} Scheduler
  [6] pause rw — '1' -> pause/suspend scheduler , '0' -> resume scheduler
  [5] strm_en rw — '1' -> Streaming input enable, '0' No streaming input
  [3:1] pipeline_num rw — Pipeline Number of HWA{i} Scheduler
  [0] sch_en rw — scheduler enable; write '1' to enable scheduler
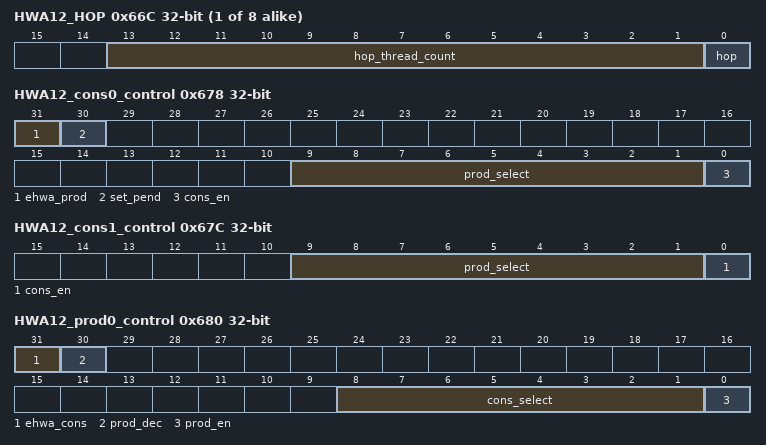
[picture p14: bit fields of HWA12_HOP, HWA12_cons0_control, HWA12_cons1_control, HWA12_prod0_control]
{0x18C+0x68*i} HWA{i}_HOP (i=12..19) — Scheduler HOP Control Register. Help in detecting eop within scheduler. Once configured, it counts task/channel starts and stops issuing further starts. Specifically useful for Head of pipe dma scheduler .
  fields as HWA6_HOP
0x678 HWA12_cons0_control access per field — Controlling consumer socket 0 for HWA12
  [31] ehwa_prod rw — '1' -> spare consumer is connected to external host producer , '0' --> no external host producer
  [30] set_pend wo — writing '1' sets pend on consumer socket
  [9:1] prod_select rw — producer select for HWA12 cons socket 0
  [0] cons_en rw — '1' -> Consumer socket 0 enable , '0' Disable
0x67C HWA12_cons1_control — Controlling consumer socket 1 for HWA12
  [9:1] prod_select — producer select for HWA12 cons socket 1
  [0] cons_en — '1' -> Consumer socket 1 enable , '0' Disable
0x680 HWA12_prod0_control access per field — Controlling producer socket0 for HWA12
  [31] ehwa_cons rw — '1' -> spare consumer is connected to external host consumer , '0' --> no external host consumer
  [30] prod_dec wo — writing '1' decrement prod count value
  [8:1] cons_select rw — consumer select for HWA12 prod socket 0. Used in decrementing count of producer buffer
  [0] prod_en rw — '1' -> Producer socket 0 enable , '0' Disable
{0x684+0x14*i} HWA12_prod{i}_buf_control (i=0..3) — Controlling producer socket{i} buffer for HWA12
  fields as HWA5_prod0_buf_control
{0x688+0x14*i} HWA12_prod{i}_count access per field (i=0..3) — Defining count values for pre/post load for generating pend by HWA12 prod{i}
  fields as HWA5_prod0_count
{0x68C+0x14*i} HWA12_pa{i}_control (i=0..2) — control register to manage pattern adapter on HWA12 prod socket{i}
  fields as HWA7_pa0_control
{0x690+0x14*i} HWA12_pa{i}_prodcount access per field (i=0..2) — count values for HWA12 prod socket{i}
  fields as HWA7_pa0_prodcount
{0x680+0x14*i} HWA12_prod{i}_control (i=1..3) — Controlling producer socket{i} for HWA12
  [8:1] cons_select — consumer select for HWA12 prod socket {i}. Used in decrementing count of producer buffer
  [0] prod_en — '1' -> Producer socket 0 enable , '0' Disable
0x6D8 GLBCE_TILE_OUT_POS — Tile processing signals
  [31:16] TOP — Tile Top position
  [15:0] LEFT — Tile Left position
0x6E0 HWA13_cons0_control access per field — Controlling consumer socket 0 for HWA13
  [31] ehwa_prod rw — '1' -> spare consumer is connected to external host producer , '0' --> no external host producer
  [30] set_pend wo — writing '1' sets pend on consumer socket
  [9:1] prod_select rw — producer select for HWA13 cons socket 0
  [0] cons_en rw — '1' -> Consumer socket 0 enable , '0' Disable
0x6E0 GLBCE_TILE_OUT_SIZE — Tile processing signals
  [31:16] HEIGHT — Tile Height
  [15:0] WIDTH — Tile Width
0x6E4 HWA13_cons1_control — Controlling consumer socket 1 for HWA13
  [9:1] prod_select — producer select for HWA13 cons socket 1
  [0] cons_en — '1' -> Consumer socket 1 enable , '0' Disable
0x6E8 HWA13_prod0_control access per field — Controlling producer socket0 for HWA13
  [31] ehwa_cons rw — '1' -> spare consumer is connected to external host consumer , '0' --> no external host consumer
  [30] prod_dec wo — writing '1' decrement prod count value
  [8:1] cons_select rw — consumer select for HWA13 prod socket 0. Used in decrementing count of producer buffer
  [0] prod_en rw — '1' -> Producer socket 0 enable , '0' Disable
0x6E8 GLBCE_TILE_CONTROL access per field — Tile Processing Control register
  [4] LAST rw — Last time
  [3] COLLECTION_DISABLE rw — Statistics collection disable
  [2] UPDATE_DSABLE rw — Statistics update disable
  [0] ENABLE rw — Tile processing Enable
{0x6EC+0x14*i} HWA13_prod{i}_buf_control (i=0..3) — Controlling producer socket{i} buffer for HWA13
  fields as HWA5_prod0_buf_control
0x6EC GLBCE_OUTPUT_FLAGS ro — Tile status register
  [15:0] TILE_STATUS
{0x6F0+0x14*i} HWA13_prod{i}_count access per field (i=0..3) — Defining count values for pre/post load for generating pend by HWA13 prod{i}
  fields as HWA5_prod0_count
{0x6F4+0x14*i} HWA13_pa{i}_control (i=0..2) — control register to manage pattern adapter on HWA13 prod socket{i}
  fields as HWA7_pa0_control
{0x6F8+0x14*i} HWA13_pa{i}_prodcount access per field (i=0..2) — count values for HWA13 prod socket{i}
  fields as HWA7_pa0_prodcount
{0x6E8+0x14*i} HWA13_prod{i}_control (i=1..3) — Controlling producer socket{i} for HWA13
  [8:1] cons_select — consumer select for HWA13 prod socket {i}. Used in decrementing count of producer buffer
  [0] prod_en — '1' -> Producer socket 0 enable , '0' Disable
{0x700+0x20*i} status_clr_reg_level_vpac_out_{i}_0 (i=0..5) — Status Clear Register {8i}
  [24] status_level_vpac_out_{i}_viss0_lse_out_fr_start_evt_clr — Status ,write 1 to clear, for level_vpac_out_{i}_en_viss0_lse_out_fr_start_evt
  [23] status_level_vpac_out_{i}_viss0_lse_cal_vp_err_clr — Status ,write 1 to clear, for level_vpac_out_{i}_en_viss0_lse_cal_vp_err
  [22] status_level_vpac_out_{i}_viss0_lse_sl2_wr_err_clr — Status ,write 1 to clear, for level_vpac_out_{i}_en_viss0_lse_sl2_wr_err
  [21] status_level_vpac_out_{i}_viss0_lse_sl2_rd_err_clr — Status ,write 1 to clear, for level_vpac_out_{i}_en_viss0_lse_sl2_rd_err
  [20] status_level_vpac_out_{i}_viss0_lse_fr_done_evt_clr — Status ,write 1 to clear, for level_vpac_out_{i}_en_viss0_lse_fr_done_evt
  [19] status_level_vpac_out_{i}_viss0_ee_syncovf_err_clr — Status ,write 1 to clear, for level_vpac_out_{i}_en_viss0_ee_syncovf_err
  [18] status_level_vpac_out_{i}_viss0_ee_cfg_err_clr — Status ,write 1 to clear, for level_vpac_out_{i}_en_viss0_ee_cfg_err
  [17] status_level_vpac_out_{i}_viss0_fcc_hist_read_err_clr — Status ,write 1 to clear, for level_vpac_out_{i}_en_viss0_fcc_hist_read_err
  [16] status_level_vpac_out_{i}_viss0_fcc_outif_ovf_err_clr — Status ,write 1 to clear, for level_vpac_out_{i}_en_viss0_fcc_outif_ovf_err
  [15] status_level_vpac_out_{i}_viss0_fcc_cfg_err_clr — Status ,write 1 to clear, for level_vpac_out_{i}_en_viss0_fcc_cfg_err
  [14] status_level_vpac_out_{i}_viss0_fcfa_cfg_err_clr — Status ,write 1 to clear, for level_vpac_out_{i}_en_viss0_fcfa_cfg_err
  [13] status_level_vpac_out_{i}_viss0_glbce_vp_err_clr — Status ,write 1 to clear, for level_vpac_out_{i}_en_viss0_glbce_vp_err
  [12] status_level_vpac_out_{i}_viss0_glbce_vsync_err_clr — Status ,write 1 to clear, for level_vpac_out_{i}_en_viss0_glbce_vsync_err
  [11] status_level_vpac_out_{i}_viss0_glbce_hsync_err_clr — Status ,write 1 to clear, for level_vpac_out_{i}_en_viss0_glbce_hsync_err
  [10] status_level_vpac_out_{i}_viss0_glbce_filt_done_clr — Status ,write 1 to clear, for level_vpac_out_{i}_en_viss0_glbce_filt_done
  [9] status_level_vpac_out_{i}_viss0_glbce_filt_start_clr — Status ,write 1 to clear, for level_vpac_out_{i}_en_viss0_glbce_filt_start
  [8] status_level_vpac_out_{i}_viss0_glbce_cfg_err_clr — Status ,write 1 to clear, for level_vpac_out_{i}_en_viss0_glbce_cfg_err
  [7] status_level_vpac_out_{i}_viss0_nsf4v_vblank_err_clr — Status ,write 1 to clear, for level_vpac_out_{i}_en_viss0_nsf4v_vblank_err
  [6] status_level_vpac_out_{i}_viss0_nsf4v_hblank_err_clr — Status ,write 1 to clear, for level_vpac_out_{i}_en_viss0_nsf4v_hblank_err
  [5] status_level_vpac_out_{i}_viss0_nsf4v_linemem_cfg_err_clr — Status ,write 1 to clear, for level_vpac_out_{i}_en_viss0_nsf4v_linemem_cfg_err
  [4] status_level_vpac_out_{i}_viss0_rawfe_h3a_buf_ovrflow_pulse_clr — Status ,write 1 to clear, for level_vpac_out_{i}_en_viss0_rawfe_h3a_buf_ovrflow_pulse
  [3] status_level_vpac_out_{i}_viss0_rawfe_h3a_pulse_clr — Status ,write 1 to clear, for level_vpac_out_{i}_en_viss0_rawfe_h3a_pulse
  [2] status_level_vpac_out_{i}_viss0_rawfe_af_pulse_clr — Status ,write 1 to clear, for level_vpac_out_{i}_en_viss0_rawfe_af_pulse
  [1] status_level_vpac_out_{i}_viss0_rawfe_aew_pulse_clr — Status ,write 1 to clear, for level_vpac_out_{i}_en_viss0_rawfe_aew_pulse
  [0] status_level_vpac_out_{i}_viss0_rawfe_cfg_err_clr — Status ,write 1 to clear, for level_vpac_out_{i}_en_viss0_rawfe_cfg_err
{0x704+0x20*i} status_clr_reg_level_vpac_out_{i}_1 (i=0..5) — Status Clear Register {8i+1}
  [8] status_level_vpac_out_{i}_ldc0_vbusm_rd_err_clr — Status ,write 1 to clear, for level_vpac_out_{i}_en_ldc0_vbusm_rd_err
  [7] status_level_vpac_out_{i}_ldc0_sl2_wr_err_clr — Status ,write 1 to clear, for level_vpac_out_{i}_en_ldc0_sl2_wr_err
  [6] status_level_vpac_out_{i}_ldc0_fr_done_evt_clr — Status ,write 1 to clear, for level_vpac_out_{i}_en_ldc0_fr_done_evt
  [5] status_level_vpac_out_{i}_ldc0_int_szovf_clr — Status ,write 1 to clear, for level_vpac_out_{i}_en_ldc0_int_szovf
  [4] status_level_vpac_out_{i}_ldc0_ifr_outofbound_clr — Status ,write 1 to clear, for level_vpac_out_{i}_en_ldc0_ifr_outofbound
  [3] status_level_vpac_out_{i}_ldc0_mesh_iblk_memovf_clr — Status ,write 1 to clear, for level_vpac_out_{i}_en_ldc0_mesh_iblk_memovf
  [2] status_level_vpac_out_{i}_ldc0_pix_iblk_memovf_clr — Status ,write 1 to clear, for level_vpac_out_{i}_en_ldc0_pix_iblk_memovf
  [1] status_level_vpac_out_{i}_ldc0_mesh_iblk_outofbound_clr — Status ,write 1 to clear, for level_vpac_out_{i}_en_ldc0_mesh_iblk_outofbound
  [0] status_level_vpac_out_{i}_ldc0_pix_iblk_outofbound_clr — Status ,write 1 to clear, for level_vpac_out_{i}_en_ldc0_pix_iblk_outofbound
{0x708+0x20*i} status_clr_reg_level_vpac_out_{i}_2 (i=0..5) — Status Clear Register {8i+2}
  [10] status_level_vpac_out_{i}_nf_sl2_rd_err_clr — Status ,write 1 to clear, for level_vpac_out_{i}_en_nf_sl2_rd_err
  [9] status_level_vpac_out_{i}_nf_sl2_wr_err_clr — Status ,write 1 to clear, for level_vpac_out_{i}_en_nf_sl2_wr_err
  [8] status_level_vpac_out_{i}_nf_frame_done_clr — Status ,write 1 to clear, for level_vpac_out_{i}_en_nf_frame_done
  [3] status_level_vpac_out_{i}_msc_lse_sl2_wr_err_clr — Status ,write 1 to clear, for level_vpac_out_{i}_en_msc_lse_sl2_wr_err
  [2] status_level_vpac_out_{i}_msc_lse_sl2_rd_err_clr — Status ,write 1 to clear, for level_vpac_out_{i}_en_msc_lse_sl2_rd_err
  [1] status_level_vpac_out_{i}_msc_lse_fr_done_evt_1_clr — Status ,write 1 to clear, for level_vpac_out_{i}_en_msc_lse_fr_done_evt_1
  [0] status_level_vpac_out_{i}_msc_lse_fr_done_evt_0_clr — Status ,write 1 to clear, for level_vpac_out_{i}_en_msc_lse_fr_done_evt_0
{0x70C+0x20*i} status_clr_reg_level_vpac_out_{i}_3 (i=0..5) — Status Clear Register {8i+3}
  [26] status_level_vpac_out_{i}_watchdogtimer_err_6_clr — Status ,write 1 to clear, for level_vpac_out_{i}_en_watchdogtimer_err_6
  [25] status_level_vpac_out_{i}_watchdogtimer_err_5_clr — Status ,write 1 to clear, for level_vpac_out_{i}_en_watchdogtimer_err_5
  [24] status_level_vpac_out_{i}_watchdogtimer_err_4_clr — Status ,write 1 to clear, for level_vpac_out_{i}_en_watchdogtimer_err_4
  [22] status_level_vpac_out_{i}_watchdogtimer_err_2_clr — Status ,write 1 to clear, for level_vpac_out_{i}_en_watchdogtimer_err_2
  [20] status_level_vpac_out_{i}_watchdogtimer_err_0_clr — Status ,write 1 to clear, for level_vpac_out_{i}_en_watchdogtimer_err_0
  [15] status_level_vpac_out_{i}_spare_dec_1_clr — Status ,write 1 to clear, for level_vpac_out_{i}_en_spare_dec_1
  [14] status_level_vpac_out_{i}_spare_dec_0_clr — Status ,write 1 to clear, for level_vpac_out_{i}_en_spare_dec_0
  [13] status_level_vpac_out_{i}_tdone_6_clr — Status ,write 1 to clear, for level_vpac_out_{i}_en_tdone_6
  [12] status_level_vpac_out_{i}_tdone_5_clr — Status ,write 1 to clear, for level_vpac_out_{i}_en_tdone_5
  [11] status_level_vpac_out_{i}_tdone_4_clr — Status ,write 1 to clear, for level_vpac_out_{i}_en_tdone_4
  [9] status_level_vpac_out_{i}_tdone_2_clr — Status ,write 1 to clear, for level_vpac_out_{i}_en_tdone_2
  [7] status_level_vpac_out_{i}_tdone_0_clr — Status ,write 1 to clear, for level_vpac_out_{i}_en_tdone_0
  [n] status_level_vpac_out_{i}_pipe_done_{n}_clr (n=0..6) — Status ,write 1 to clear, for level_vpac_out_{i}_en_pipe_done_{n}
{0x710+0x20*i} status_clr_reg_level_vpac_out_{i}_4 (i=0..5) — Status Clear Register {8i+4}
  [n] status_level_vpac_out_{i}_utc0_complete_{n}_clr (n=0..31) — Status ,write 1 to clear, for level_vpac_out_{i}_en_utc0_complete_{n}
